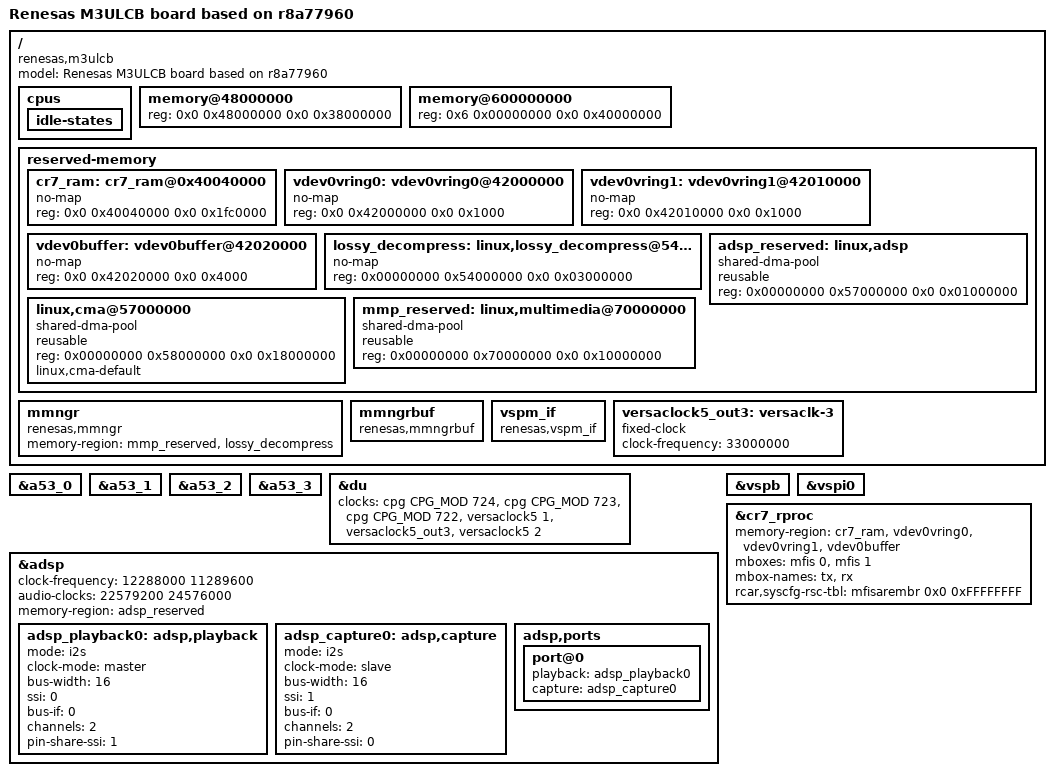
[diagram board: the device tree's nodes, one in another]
// SPDX-License-Identifier: GPL-2.0
/*
 * Device Tree Source for the M3ULCB (R-Car Starter Kit Pro) board
 *
 * Copyright (C) 2016 Renesas Electronics Corp.
 * Copyright (C) 2016 Cogent Embedded, Inc.
 */

/dts-v1/;
#include "r8a77960.dtsi"
#include "ulcb.dtsi"

/ {
	model = "Renesas M3ULCB board based on r8a77960";
	compatible = "renesas,m3ulcb", "renesas,r8a7796";

	cpus {
		idle-states {
			/delete-node/ cpu-sleep-1;
		};
	};

	memory@48000000 {
		device_type = "memory";
		/* first 128MB is reserved for secure area. */
		reg = <0x0 0x48000000 0x0 0x38000000>;
	};

	memory@600000000 {
		device_type = "memory";
		reg = <0x6 0x00000000 0x0 0x40000000>;
	};

	reserved-memory {
		#address-cells = <2>;
		#size-cells = <2>;
		ranges;

		cr7_ram: cr7_ram@0x40040000 {
			no-map;
			reg = <0x0 0x40040000 0x0 0x1fc0000>;
		};

		vdev0vring0: vdev0vring0@42000000 {
			no-map;
			reg = <0x0 0x42000000 0x0 0x1000>;
		};

		vdev0vring1: vdev0vring1@42010000 {
			no-map;
			reg = <0x0 0x42010000 0x0 0x1000>;
		};

		vdev0buffer: vdev0buffer@42020000 {
			no-map;
			reg = <0x0 0x42020000 0x0 0x4000>;
		};

		/* device specific region for Lossy Decompression */
		lossy_decompress: linux,lossy_decompress@54000000 {
			no-map;
			reg = <0x00000000 0x54000000 0x0 0x03000000>;
		};

		/* For Audio DSP */
		adsp_reserved: linux,adsp {
			compatible = "shared-dma-pool";
			reusable;
			reg = <0x00000000 0x57000000 0x0 0x01000000>;
		};

		/* global autoconfigured region for contiguous allocations */
		linux,cma@57000000 {
			compatible = "shared-dma-pool";
			reusable;
			reg = <0x00000000 0x58000000 0x0 0x18000000>;
			linux,cma-default;
		};

		/* device specific region for contiguous allocations */
		mmp_reserved: linux,multimedia@70000000 {
			compatible = "shared-dma-pool";
			reusable;
			reg = <0x00000000 0x70000000 0x0 0x10000000>;
		};
	};

	mmngr {
		compatible = "renesas,mmngr";
		memory-region = <&mmp_reserved>, <&lossy_decompress>;
	};

	mmngrbuf {
		compatible = "renesas,mmngrbuf";
	};

	vspm_if {
		compatible = "renesas,vspm_if";
	};

	versaclock5_out3: versaclk-3 {
		compatible = "fixed-clock";
		#clock-cells = <0>;
		/* Initial value of versaclock out3 */
		clock-frequency = <33000000>;
	};
};

&a53_0 {
	/delete-property/ cpu-idle-states;
};

&a53_1 {
	/delete-property/ cpu-idle-states;
};

&a53_2 {
	/delete-property/ cpu-idle-states;
};

&a53_3 {
	/delete-property/ cpu-idle-states;
};

&du {
	clocks = <&cpg CPG_MOD 724>,
		 <&cpg CPG_MOD 723>,
		 <&cpg CPG_MOD 722>,
		 <&versaclock5 1>,
		 <&versaclock5_out3>,
		 <&versaclock5 2>;
	clock-names = "du.0", "du.1", "du.2",
		      "dclkin.0", "dclkin.1", "dclkin.2";
};

&adsp {
	status = "okay";
	clock-frequency = <12288000 11289600>;
	audio-clocks = <22579200 24576000>;
	memory-region = <&adsp_reserved>;

	/* ADSP playback setting for ak4613 */
	adsp_playback0: adsp,playback {
		mode  = "i2s";
		clock-mode = "master";
		bus-width = <16>;
		ssi = <0>;
		bus-if = <0>;
		channels = <2>;
		pin-share-ssi = <1>;
	};

	/* ADSP capture setting for ak4613 */
	adsp_capture0: adsp,capture {
		mode  = "i2s";
		clock-mode = "slave";
		bus-width = <16>;
		ssi = <1>;
		bus-if = <0>;
		channels = <2>;
		pin-share-ssi = <0>;
	};
	
	adsp,ports {
		port@0 {
			playback = <&adsp_playback0>;
			capture  = <&adsp_capture0>;
		};
	};
};

&vspb {
	status = "okay";
};

&vspi0 {
	status = "okay";
};

&cr7_rproc {
	memory-region = <&cr7_ram>, <&vdev0vring0>, <&vdev0vring1>, <&vdev0buffer>;
	mboxes = <&mfis 0>, <&mfis 1>;
	mbox-names = "tx", "rx";
	rcar,syscfg-rsc-tbl = <&mfisarembr 0x0 0xFFFFFFFF>;
	status = "okay";
};
